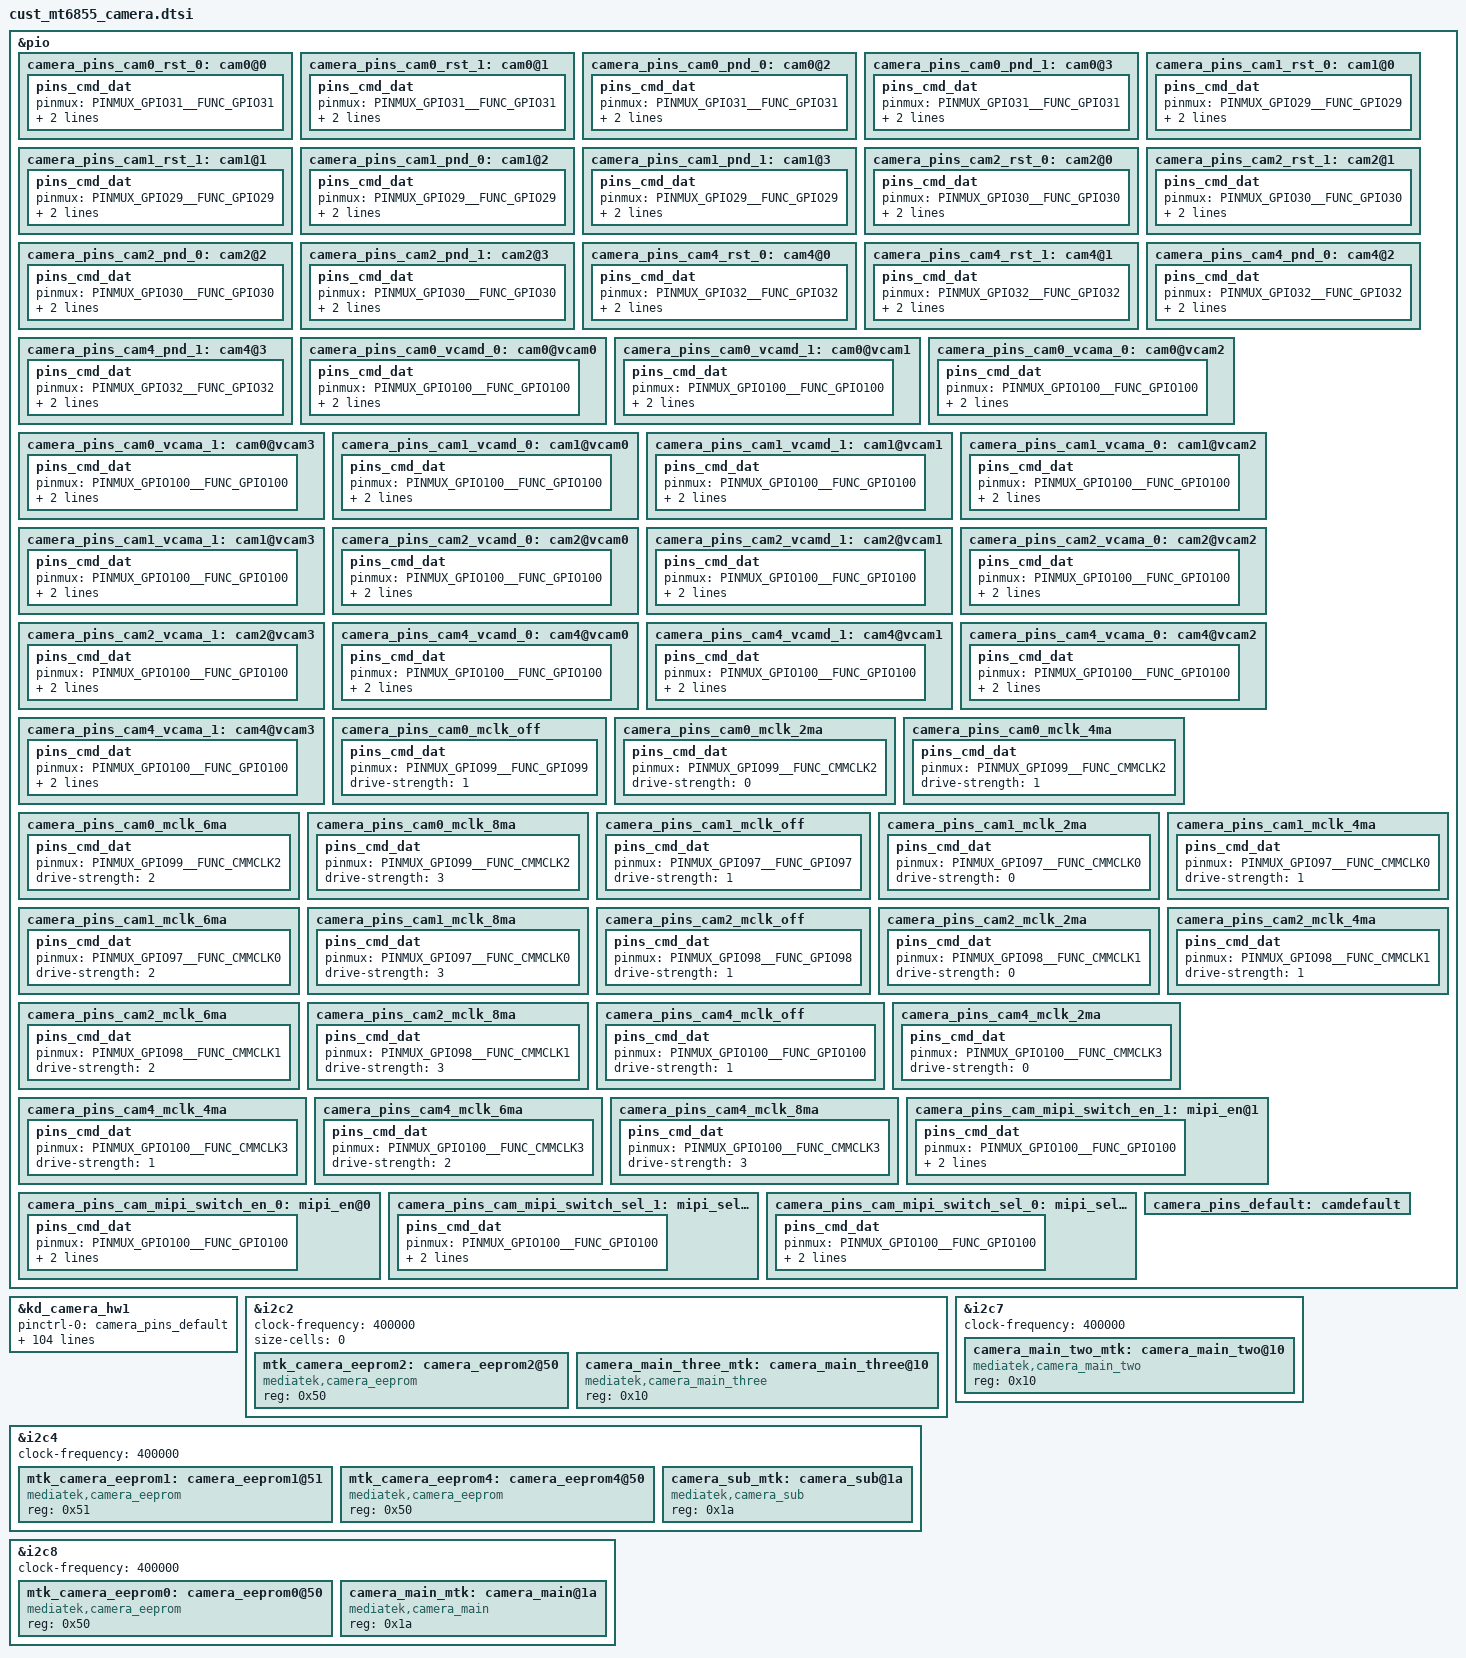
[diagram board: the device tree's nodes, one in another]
// SPDX-License-Identifier: GPL-2.0
/* Copyright (c) 2020 MediaTek Inc. */
/* CAMERA GPIO standardization */
&pio {
	camera_pins_cam0_rst_0: cam0@0 {
		pins_cmd_dat {
			pinmux = <PINMUX_GPIO31__FUNC_GPIO31>;
			slew-rate = <1>;
			output-low;
		};
	};
	camera_pins_cam0_rst_1: cam0@1 {
		pins_cmd_dat {
			pinmux = <PINMUX_GPIO31__FUNC_GPIO31>;
			slew-rate = <1>;
			output-high;
		};
	};
	camera_pins_cam0_pnd_0: cam0@2 {
		pins_cmd_dat {
			pinmux = <PINMUX_GPIO31__FUNC_GPIO31>;
			slew-rate = <1>;
			output-low;
		};
	};
	camera_pins_cam0_pnd_1: cam0@3 {
		pins_cmd_dat {
			pinmux = <PINMUX_GPIO31__FUNC_GPIO31>;
			slew-rate = <1>;
			output-high;
		};
	};
	camera_pins_cam1_rst_0: cam1@0 {
		pins_cmd_dat {
			pinmux = <PINMUX_GPIO29__FUNC_GPIO29>;
			slew-rate = <1>;
			output-low;
		};
	};
	camera_pins_cam1_rst_1: cam1@1 {
		pins_cmd_dat {
			pinmux = <PINMUX_GPIO29__FUNC_GPIO29>;
			slew-rate = <1>;
			output-high;
		};
	};
	camera_pins_cam1_pnd_0: cam1@2 {
		pins_cmd_dat {
			pinmux = <PINMUX_GPIO29__FUNC_GPIO29>;
			slew-rate = <1>;
			output-low;
		};
	};
	camera_pins_cam1_pnd_1: cam1@3 {
		pins_cmd_dat {
			pinmux = <PINMUX_GPIO29__FUNC_GPIO29>;
			slew-rate = <1>;
			output-high;
		};
	};
	camera_pins_cam2_rst_0: cam2@0 {
		pins_cmd_dat {
			pinmux = <PINMUX_GPIO30__FUNC_GPIO30>;
			slew-rate = <1>;
			output-low;
		};
	};
	camera_pins_cam2_rst_1: cam2@1 {
		pins_cmd_dat {
			pinmux = <PINMUX_GPIO30__FUNC_GPIO30>;
			slew-rate = <1>;
			output-high;
		};
	};
	camera_pins_cam2_pnd_0: cam2@2 {
		pins_cmd_dat {
			pinmux = <PINMUX_GPIO30__FUNC_GPIO30>;
			slew-rate = <1>;
			output-low;
		};
	};
	camera_pins_cam2_pnd_1: cam2@3 {
		pins_cmd_dat {
			pinmux = <PINMUX_GPIO30__FUNC_GPIO30>;
			slew-rate = <1>;
			output-high;
		};
	};
	camera_pins_cam4_rst_0: cam4@0 {
		pins_cmd_dat {
			pinmux = <PINMUX_GPIO32__FUNC_GPIO32>;
			slew-rate = <1>;
			output-low;
		};
	};
	camera_pins_cam4_rst_1: cam4@1 {
		pins_cmd_dat {
			pinmux = <PINMUX_GPIO32__FUNC_GPIO32>;
			slew-rate = <1>;
			output-high;
		};
	};
	camera_pins_cam4_pnd_0: cam4@2 {
		pins_cmd_dat {
			pinmux = <PINMUX_GPIO32__FUNC_GPIO32>;
			slew-rate = <1>;
			output-low;
		};
	};
	camera_pins_cam4_pnd_1: cam4@3 {
		pins_cmd_dat {
			pinmux = <PINMUX_GPIO32__FUNC_GPIO32>;
			slew-rate = <1>;
			output-high;
		};
	};
	camera_pins_cam0_vcamd_0: cam0@vcam0 {
		pins_cmd_dat {
			pinmux = <PINMUX_GPIO100__FUNC_GPIO100>;
			slew-rate = <1>;
			output-low;
		};
	};
	camera_pins_cam0_vcamd_1: cam0@vcam1 {
		pins_cmd_dat {
			pinmux = <PINMUX_GPIO100__FUNC_GPIO100>;
			slew-rate = <1>;
			output-high;
		};
	};
	camera_pins_cam0_vcama_0: cam0@vcam2 {
		pins_cmd_dat {
			pinmux = <PINMUX_GPIO100__FUNC_GPIO100>;
			slew-rate = <1>;
			output-low;
		};
	};
	camera_pins_cam0_vcama_1: cam0@vcam3 {
		pins_cmd_dat {
			pinmux = <PINMUX_GPIO100__FUNC_GPIO100>;
			slew-rate = <1>;
			output-high;
		};
	};
	camera_pins_cam1_vcamd_0: cam1@vcam0 {
		pins_cmd_dat {
			pinmux = <PINMUX_GPIO100__FUNC_GPIO100>;
			slew-rate = <1>;
			output-low;
		};
	};
	camera_pins_cam1_vcamd_1: cam1@vcam1 {
		pins_cmd_dat {
			pinmux = <PINMUX_GPIO100__FUNC_GPIO100>;
			slew-rate = <1>;
			output-high;
		};
	};
	camera_pins_cam1_vcama_0: cam1@vcam2 {
		pins_cmd_dat {
			pinmux = <PINMUX_GPIO100__FUNC_GPIO100>;
			slew-rate = <1>;
			output-low;
		};
	};
	camera_pins_cam1_vcama_1: cam1@vcam3 {
		pins_cmd_dat {
			pinmux = <PINMUX_GPIO100__FUNC_GPIO100>;
			slew-rate = <1>;
			output-high;
		};
	};
	camera_pins_cam2_vcamd_0: cam2@vcam0 {
		pins_cmd_dat {
			pinmux = <PINMUX_GPIO100__FUNC_GPIO100>;
			slew-rate = <1>;
			output-low;
		};
	};
	camera_pins_cam2_vcamd_1: cam2@vcam1 {
		pins_cmd_dat {
			pinmux = <PINMUX_GPIO100__FUNC_GPIO100>;
			slew-rate = <1>;
			output-high;
		};
	};
	camera_pins_cam2_vcama_0: cam2@vcam2 {
		pins_cmd_dat {
			pinmux = <PINMUX_GPIO100__FUNC_GPIO100>;
			slew-rate = <1>;
			output-low;
		};
	};
	camera_pins_cam2_vcama_1: cam2@vcam3 {
		pins_cmd_dat {
			pinmux = <PINMUX_GPIO100__FUNC_GPIO100>;
			slew-rate = <1>;
			output-high;
		};
	};
	camera_pins_cam4_vcamd_0: cam4@vcam0 {
		pins_cmd_dat {
			pinmux = <PINMUX_GPIO100__FUNC_GPIO100>;
			slew-rate = <1>;
			output-low;
		};
	};
	camera_pins_cam4_vcamd_1: cam4@vcam1 {
		pins_cmd_dat {
			pinmux = <PINMUX_GPIO100__FUNC_GPIO100>;
			slew-rate = <1>;
			output-high;
		};
	};
	camera_pins_cam4_vcama_0: cam4@vcam2 {
		pins_cmd_dat {
			pinmux = <PINMUX_GPIO100__FUNC_GPIO100>;
			slew-rate = <1>;
			output-low;
		};
	};
	camera_pins_cam4_vcama_1: cam4@vcam3 {
		pins_cmd_dat {
			pinmux = <PINMUX_GPIO100__FUNC_GPIO100>;
			slew-rate = <1>;
			output-high;
		};
	};
	camera_pins_cam0_mclk_off: camera_pins_cam0_mclk_off {
		pins_cmd_dat {
			pinmux = <PINMUX_GPIO99__FUNC_GPIO99>;
			drive-strength = <1>;
		};
	};
	camera_pins_cam0_mclk_2ma: camera_pins_cam0_mclk_2ma {
		pins_cmd_dat {
			pinmux = <PINMUX_GPIO99__FUNC_CMMCLK2>;
			drive-strength = <0>;
		};
	};
	camera_pins_cam0_mclk_4ma: camera_pins_cam0_mclk_4ma {
		pins_cmd_dat {
			pinmux = <PINMUX_GPIO99__FUNC_CMMCLK2>;
			drive-strength = <1>;
		};
	};
	camera_pins_cam0_mclk_6ma: camera_pins_cam0_mclk_6ma {
		pins_cmd_dat {
			pinmux = <PINMUX_GPIO99__FUNC_CMMCLK2>;
			drive-strength = <2>;
		};
	};
	camera_pins_cam0_mclk_8ma: camera_pins_cam0_mclk_8ma {
		pins_cmd_dat {
			pinmux = <PINMUX_GPIO99__FUNC_CMMCLK2>;
			drive-strength = <3>;
		};
	};
	camera_pins_cam1_mclk_off: camera_pins_cam1_mclk_off {
		pins_cmd_dat {
			pinmux = <PINMUX_GPIO97__FUNC_GPIO97>;
			drive-strength = <1>;
		};
	};
	camera_pins_cam1_mclk_2ma: camera_pins_cam1_mclk_2ma {
		pins_cmd_dat {
			pinmux = <PINMUX_GPIO97__FUNC_CMMCLK0>;
			drive-strength = <0>;
		};
	};
	camera_pins_cam1_mclk_4ma: camera_pins_cam1_mclk_4ma {
		pins_cmd_dat {
			pinmux = <PINMUX_GPIO97__FUNC_CMMCLK0>;
			drive-strength = <1>;
		};
	};
	camera_pins_cam1_mclk_6ma: camera_pins_cam1_mclk_6ma {
		pins_cmd_dat {
			pinmux = <PINMUX_GPIO97__FUNC_CMMCLK0>;
			drive-strength = <2>;
		};
	};
	camera_pins_cam1_mclk_8ma: camera_pins_cam1_mclk_8ma {
		pins_cmd_dat {
			pinmux = <PINMUX_GPIO97__FUNC_CMMCLK0>;
			drive-strength = <3>;
		};
	};
	camera_pins_cam2_mclk_off: camera_pins_cam2_mclk_off {
		pins_cmd_dat {
			pinmux = <PINMUX_GPIO98__FUNC_GPIO98>;
			drive-strength = <1>;
		};
	};
	camera_pins_cam2_mclk_2ma: camera_pins_cam2_mclk_2ma {
		pins_cmd_dat {
			pinmux = <PINMUX_GPIO98__FUNC_CMMCLK1>;
			drive-strength = <0>;
		};
	};
	camera_pins_cam2_mclk_4ma: camera_pins_cam2_mclk_4ma {
		pins_cmd_dat {
			pinmux = <PINMUX_GPIO98__FUNC_CMMCLK1>;
			drive-strength = <1>;
		};
	};
	camera_pins_cam2_mclk_6ma: camera_pins_cam2_mclk_6ma {
		pins_cmd_dat {
			pinmux = <PINMUX_GPIO98__FUNC_CMMCLK1>;
			drive-strength = <2>;
		};
	};
	camera_pins_cam2_mclk_8ma: camera_pins_cam2_mclk_8ma {
		pins_cmd_dat {
			pinmux = <PINMUX_GPIO98__FUNC_CMMCLK1>;
			drive-strength = <3>;
		};
	};
	camera_pins_cam4_mclk_off: camera_pins_cam4_mclk_off {
		pins_cmd_dat {
			pinmux = <PINMUX_GPIO100__FUNC_GPIO100>;
			drive-strength = <1>;
		};
	};
	camera_pins_cam4_mclk_2ma: camera_pins_cam4_mclk_2ma {
		pins_cmd_dat {
			pinmux = <PINMUX_GPIO100__FUNC_CMMCLK3>;
			drive-strength = <0>;
		};
	};
	camera_pins_cam4_mclk_4ma: camera_pins_cam4_mclk_4ma {
		pins_cmd_dat {
			pinmux = <PINMUX_GPIO100__FUNC_CMMCLK3>;
			drive-strength = <1>;
		};
	};
	camera_pins_cam4_mclk_6ma: camera_pins_cam4_mclk_6ma {
		pins_cmd_dat {
			pinmux = <PINMUX_GPIO100__FUNC_CMMCLK3>;
			drive-strength = <2>;
		};
	};
	camera_pins_cam4_mclk_8ma: camera_pins_cam4_mclk_8ma {
		pins_cmd_dat {
			pinmux = <PINMUX_GPIO100__FUNC_CMMCLK3>;
			drive-strength = <3>;
		};
	};
	camera_pins_cam_mipi_switch_en_1: mipi_en@1 {
		pins_cmd_dat {
			pinmux = <PINMUX_GPIO100__FUNC_GPIO100>;
			slew-rate = <1>;
			output-high;
		};
	};
	camera_pins_cam_mipi_switch_en_0: mipi_en@0 {
		pins_cmd_dat {
			pinmux = <PINMUX_GPIO100__FUNC_GPIO100>;
			slew-rate = <1>;
			output-low;
		};
	};
	camera_pins_cam_mipi_switch_sel_1: mipi_sel@1 {
		pins_cmd_dat {
			pinmux = <PINMUX_GPIO100__FUNC_GPIO100>;
			slew-rate = <1>;
			output-high;
		};
	};
	camera_pins_cam_mipi_switch_sel_0: mipi_sel@0 {
		pins_cmd_dat {
			pinmux = <PINMUX_GPIO100__FUNC_GPIO100>;
			slew-rate = <1>;
			output-low;
		};
	};
	camera_pins_default: camdefault {
	};
};
&kd_camera_hw1 {
	pinctrl-names = "default",
			"cam0_rst0", "cam0_rst1",
			"cam0_pnd0", "cam0_pnd1",
			"cam1_rst0", "cam1_rst1",
			"cam1_pnd0", "cam1_pnd1",
			"cam2_rst0", "cam2_rst1",
			"cam2_pnd0", "cam2_pnd1",
			"cam4_rst0", "cam4_rst1",
			"cam4_pnd0", "cam4_pnd1",
			"cam0_ldo_vcamd_0", "cam0_ldo_vcamd_1",
			"cam0_ldo_vcama_0", "cam0_ldo_vcama_1",
			"cam1_ldo_vcamd_0", "cam1_ldo_vcamd_1",
			"cam1_ldo_vcama_0", "cam1_ldo_vcama_1",
			"cam2_ldo_vcamd_0", "cam2_ldo_vcamd_1",
			"cam2_ldo_vcama_0", "cam2_ldo_vcama_1",
			"cam4_ldo_vcamd_0", "cam4_ldo_vcamd_1",
			"cam4_ldo_vcama_0", "cam4_ldo_vcama_1",
			"cam0_mclk_off",
			"cam0_mclk_2mA", "cam0_mclk_4mA",
			"cam0_mclk_6mA", "cam0_mclk_8mA",
			"cam1_mclk_off",
			"cam1_mclk_2mA", "cam1_mclk_4mA",
			"cam1_mclk_6mA", "cam1_mclk_8mA",
			"cam2_mclk_off",
			"cam2_mclk_2mA", "cam2_mclk_4mA",
			"cam2_mclk_6mA", "cam2_mclk_8mA",
			"cam4_mclk_off",
			"cam4_mclk_2mA", "cam4_mclk_4mA",
			"cam4_mclk_6mA", "cam4_mclk_8mA",
			"cam_mipi_switch_en_1", "cam_mipi_switch_en_0",
			"cam_mipi_switch_sel_1", "cam_mipi_switch_sel_0";
	pinctrl-0 = <&camera_pins_default>;
	pinctrl-1 = <&camera_pins_cam0_rst_0>;
	pinctrl-2 = <&camera_pins_cam0_rst_1>;
	pinctrl-3 = <&camera_pins_cam0_pnd_0>;
	pinctrl-4 = <&camera_pins_cam0_pnd_1>;
	pinctrl-5 = <&camera_pins_cam1_rst_0>;
	pinctrl-6 = <&camera_pins_cam1_rst_1>;
	pinctrl-7 = <&camera_pins_cam1_pnd_0>;
	pinctrl-8 = <&camera_pins_cam1_pnd_1>;
	pinctrl-9 = <&camera_pins_cam2_rst_0>;
	pinctrl-10 = <&camera_pins_cam2_rst_1>;
	pinctrl-11 = <&camera_pins_cam2_pnd_0>;
	pinctrl-12 = <&camera_pins_cam2_pnd_1>;
	pinctrl-13 = <&camera_pins_cam4_rst_0>;
	pinctrl-14 = <&camera_pins_cam4_rst_1>;
	pinctrl-15 = <&camera_pins_cam4_pnd_0>;
	pinctrl-16 = <&camera_pins_cam4_pnd_1>;
	pinctrl-17 = <&camera_pins_cam0_vcamd_0>;
	pinctrl-18 = <&camera_pins_cam0_vcamd_1>;
	pinctrl-19 = <&camera_pins_cam0_vcama_0>;
	pinctrl-20 = <&camera_pins_cam0_vcama_1>;
	pinctrl-21 = <&camera_pins_cam1_vcamd_0>;
	pinctrl-22 = <&camera_pins_cam1_vcamd_1>;
	pinctrl-23 = <&camera_pins_cam1_vcama_0>;
	pinctrl-24 = <&camera_pins_cam1_vcama_1>;
	pinctrl-25 = <&camera_pins_cam2_vcamd_0>;
	pinctrl-26 = <&camera_pins_cam2_vcamd_1>;
	pinctrl-27 = <&camera_pins_cam2_vcama_0>;
	pinctrl-28 = <&camera_pins_cam2_vcama_1>;
	pinctrl-29 = <&camera_pins_cam4_vcamd_0>;
	pinctrl-30 = <&camera_pins_cam4_vcamd_1>;
	pinctrl-31 = <&camera_pins_cam4_vcama_0>;
	pinctrl-32 = <&camera_pins_cam4_vcama_1>;
	pinctrl-33 = <&camera_pins_cam0_mclk_off>;
	pinctrl-34 = <&camera_pins_cam0_mclk_2ma>;
	pinctrl-35 = <&camera_pins_cam0_mclk_4ma>;
	pinctrl-36 = <&camera_pins_cam0_mclk_6ma>;
	pinctrl-37 = <&camera_pins_cam0_mclk_8ma>;
	pinctrl-38 = <&camera_pins_cam1_mclk_off>;
	pinctrl-39 = <&camera_pins_cam1_mclk_2ma>;
	pinctrl-40 = <&camera_pins_cam1_mclk_4ma>;
	pinctrl-41 = <&camera_pins_cam1_mclk_6ma>;
	pinctrl-42 = <&camera_pins_cam1_mclk_8ma>;
	pinctrl-43 = <&camera_pins_cam2_mclk_off>;
	pinctrl-44 = <&camera_pins_cam2_mclk_2ma>;
	pinctrl-45 = <&camera_pins_cam2_mclk_4ma>;
	pinctrl-46 = <&camera_pins_cam2_mclk_6ma>;
	pinctrl-47 = <&camera_pins_cam2_mclk_8ma>;
	pinctrl-48 = <&camera_pins_cam4_mclk_off>;
	pinctrl-49 = <&camera_pins_cam4_mclk_2ma>;
	pinctrl-50 = <&camera_pins_cam4_mclk_4ma>;
	pinctrl-51 = <&camera_pins_cam4_mclk_6ma>;
	pinctrl-52 = <&camera_pins_cam4_mclk_8ma>;
	pinctrl-53 = <&camera_pins_cam_mipi_switch_en_1>;
	pinctrl-54 = <&camera_pins_cam_mipi_switch_en_0>;
	pinctrl-55 = <&camera_pins_cam_mipi_switch_sel_1>;
	pinctrl-56 = <&camera_pins_cam_mipi_switch_sel_0>;

/* main (wide) : ldo4 ldo8 --- AVDD_CAM_W, DVDD_CAM_W */
	cam0_vcama-supply = <&rt5133_ldo4>;
	cam0_vcama1-supply = <&rt5133_ldo5>;
	cam0_vcamd-supply = <&rt5133_ldo8>;
	cam0_vcamio-supply = <&rt5133_ldo1>;

	/* front */
	cam1_vcama-supply = <&rt5133_ldo6>;
	cam1_vcamd-supply = <&rt5133_ldo7>;
	cam1_vcamio-supply = <&rt5133_ldo1>;

	/* main2 (tele) */
	cam2_vcama-supply = <&rt5133_ldo6>;
	cam2_vcamd-supply = <&rt5133_gpio3>;
	cam2_vcamio-supply = <&rt5133_ldo1>;

	/* main3 (ultra wide) : gpio2 gpio3 --- AVDD_CAM_F_UW, DVDD_CAM_F_UW */
	cam4_vcama-supply = <&rt5133_gpio2>;
	cam4_vcamd-supply = <&rt5133_ldo7>;
	cam4_vcamio-supply = <&rt5133_ldo1>;

	cam0_pin_mclk = "mclk";
	cam0_pin_pdn = "gpio";
	cam0_pin_rst = "gpio";
	cam0_pin_vcama = "regulator";
	cam0_pin_vcama1 = "regulator";
	cam0_pin_vcamd = "regulator";
	cam0_pin_vcamio = "regulator";
	cam1_pin_mclk = "mclk";
	cam1_pin_pdn = "gpio";
	cam1_pin_rst = "gpio";
	cam1_pin_vcama = "regulator";
	cam1_pin_vcamd = "regulator";
	cam1_pin_vcamio = "regulator";
	cam1_pin_mipi_switch_en = "gpio";
	cam1_pin_mipi_switch_sel = "gpio";
	cam2_pin_mclk = "mclk";
	cam2_pin_pdn = "gpio";
	cam2_pin_rst = "gpio";
	cam2_pin_vcama = "regulator";
	cam2_pin_vcamd = "regulator";
	cam2_pin_vcamio = "regulator";
	cam3_pin_mclk = "mclk";
	cam3_pin_pdn = "gpio";
	cam3_pin_rst = "gpio";
	cam3_pin_vcama = "regulator";
	cam3_pin_vcamd = "regulator";
	cam3_pin_vcamio = "regulator";
	cam4_pin_mclk = "mclk";
	cam4_pin_pdn = "gpio";
	cam4_pin_rst = "gpio";
	cam4_pin_vcama = "regulator";
	cam4_pin_vcamd = "regulator";
	cam4_pin_vcamio = "regulator";
	cam4_pin_mipi_switch_en = "gpio";
	cam4_pin_mipi_switch_sel = "gpio";

	status = "okay";
};
/* CAMERA GPIO end */

/* CAMERA EEPROM */
&i2c2 {
	status = "okay";
	clock-frequency = <400000>;
	#address-cells = <1>;
	size-cells = <0>;
	mtk_camera_eeprom2:camera_eeprom2@50 {
		compatible = "mediatek,camera_eeprom";
		reg = <0x50>;
		status = "okay";
	};
	camera_main_three_mtk:camera_main_three@10 {
		compatible = "mediatek,camera_main_three";
		#thermal-sensor-cells = <0>;
		reg = <0x10>;
		status = "okay";
	};
};
&i2c4 {
	status = "okay";
	clock-frequency = <400000>;
	#address-cells = <1>;
	#size-cells = <0>;
	mtk_camera_eeprom1:camera_eeprom1@51 {
		compatible = "mediatek,camera_eeprom";
		reg = <0x51>;
		status = "okay";
	};
	mtk_camera_eeprom4:camera_eeprom4@50 {
		compatible = "mediatek,camera_eeprom";
		reg = <0x50>;
		status = "okay";
	};
	camera_sub_mtk:camera_sub@1a {
		compatible = "mediatek,camera_sub";
		#thermal-sensor-cells = <0>;
		reg = <0x1a>;
		status = "okay";
	};
};
&i2c7 {
	status = "okay";
	clock-frequency = <400000>;
	#address-cells = <1>;
	#size-cells = <0>;

	camera_main_two_mtk:camera_main_two@10 {
		compatible = "mediatek,camera_main_two";
		#thermal-sensor-cells = <0>;
		reg = <0x10>;
		status = "okay";
	};
};
&i2c8 {
	status = "okay";
	clock-frequency = <400000>;
	#address-cells = <1>;
	#size-cells = <0>;
	mtk_camera_eeprom0:camera_eeprom0@50 {
		compatible = "mediatek,camera_eeprom";
		reg = <0x50>;
		status = "okay";
	};
	camera_main_mtk:camera_main@1a {
		compatible = "mediatek,camera_main";
		#thermal-sensor-cells = <0>;
		reg = <0x1a>;
		status = "okay";
	};
};
/* CAMERA EEPROM end */

/* CAMERA AF */
//&i2c2 {
//	camera_main_two_af_mtk:camera_main_two_af@0c {
//		compatible = "mediatek,camera_main_two_af";
//		reg = <0x0c>;
//		status = "okay";
//	};
//};
//&i2c8 {
//	camera_main_af_mtk:camera_main_af@72 {
//		compatible = "mediatek,camera_main_af";
//		reg = <0x72>;
//		status = "okay";
//	};
//};
//&i2c9 {
//	camera_main_three_af_mtk:camera_main_three_af@0c {
//		compatible = "mediatek,camera_main_three_af";
//		reg = <0x0c>;
//		status = "okay";
//	};
//};
/* CAMERA AF end */
